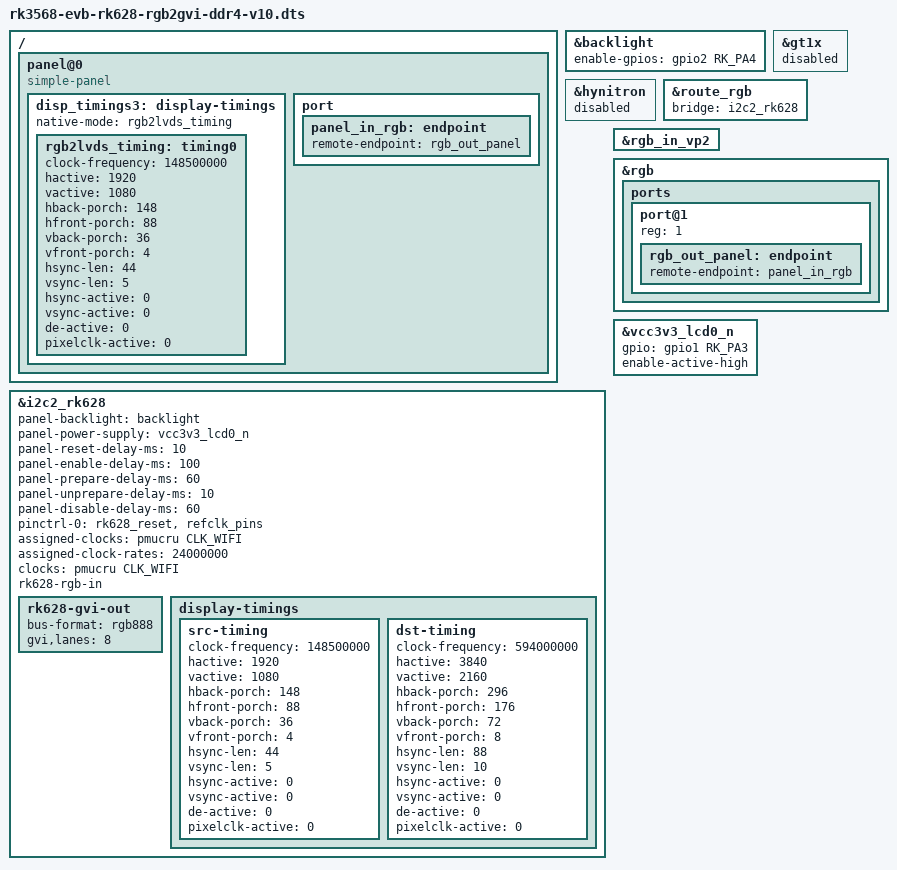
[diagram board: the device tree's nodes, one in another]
// SPDX-License-Identifier: (GPL-2.0+ OR MIT)
/*
 * Copyright (c) 2020 Rockchip Electronics Co., Ltd.
 *
 */

#include "rk3568-evb-rk628-ddr4-v10.dtsi"
#include "rk3568-android.dtsi"

/ {
	panel@0 {
		compatible = "simple-panel";

		disp_timings3: display-timings {
			native-mode = <&rgb2lvds_timing>;
			rgb2lvds_timing: timing0 {
				clock-frequency = <148500000>;
				hactive = <1920>;
				vactive = <1080>;
				hback-porch = <148>;
				hfront-porch = <88>;
				vback-porch = <36>;
				vfront-porch = <4>;
				hsync-len = <44>;
				vsync-len = <5>;
				hsync-active = <0>;
				vsync-active = <0>;
				de-active = <0>;
				pixelclk-active = <0>;
			};
		};

		port {
			panel_in_rgb: endpoint {
				remote-endpoint = <&rgb_out_panel>;
			};
		};
	};

};

&backlight {
	enable-gpios = <&gpio2 RK_PA4 GPIO_ACTIVE_HIGH>;
};

&gt1x {
	status = "disabled";
};

&hynitron {
	status = "disabled";
};

&i2c2_rk628 {
		panel-backlight = <&backlight>;
		panel-power-supply = <&vcc3v3_lcd0_n>;
		panel-reset-delay-ms = <10>;
		panel-enable-delay-ms = <100>;
		panel-prepare-delay-ms = <60>;
		panel-unprepare-delay-ms = <10>;
		panel-disable-delay-ms = <60>;
		pinctrl-names = "default";
		pinctrl-0 = <&rk628_reset &refclk_pins>;
		assigned-clocks = <&pmucru CLK_WIFI>;
		assigned-clock-rates = <24000000>;
		clocks = <&pmucru CLK_WIFI>;
		clock-names = "soc_24M";

		rk628-rgb-in;
		rk628-gvi-out {
			/* "rgb666"
			 * "rgb888"
			 * "rgb101010"
			 * "yuyv8"
			 * "yuyv10"
			 */
			bus-format = "rgb888";
			gvi,lanes = <8>;
			//"rockchip,division-mode";
			//"rockchip, gvi-frm-rst";
			status = "okay";
		};

		display-timings {
			src-timing {
				clock-frequency = <148500000>;
				hactive = <1920>;
				vactive = <1080>;
				hback-porch = <148>;
				hfront-porch = <88>;
				vback-porch = <36>;
				vfront-porch = <4>;
				hsync-len = <44>;
				vsync-len = <5>;
				hsync-active = <0>;
				vsync-active = <0>;
				de-active = <0>;
				pixelclk-active = <0>;
			};

			dst-timing {
				clock-frequency = <594000000>;
				hactive = <3840>;
				vactive = <2160>;
				hback-porch = <296>;
				hfront-porch = <176>;
				vback-porch = <72>;
				vfront-porch = <8>;
				hsync-len = <88>;
				vsync-len = <10>;
				hsync-active = <0>;
				vsync-active = <0>;
				de-active = <0>;
				pixelclk-active = <0>;
			};
	    };
};

&route_rgb {
	status = "okay";

	bridge = <&i2c2_rk628>;
};

&rgb_in_vp2 {
	status = "okay";
};

&rgb {
	status = "okay";

	ports {
		port@1 {
			reg = <1>;

			rgb_out_panel: endpoint {
				remote-endpoint = <&panel_in_rgb>;
			};
		};
	};
};

&vcc3v3_lcd0_n {
	gpio = <&gpio1 RK_PA3 GPIO_ACTIVE_HIGH>;
	enable-active-high;
};
